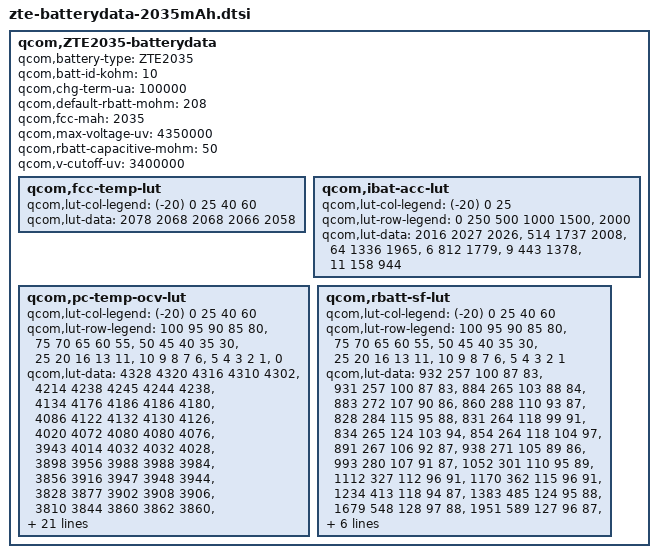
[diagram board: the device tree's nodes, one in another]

qcom,ZTE2035-batterydata {
	qcom,battery-type = "ZTE2035";
	qcom,batt-id-kohm = <10>;
	qcom,chg-term-ua = <100000>;
	qcom,default-rbatt-mohm = <208>;
	qcom,fcc-mah = <2035>;
	qcom,max-voltage-uv = <4350000>;
	qcom,rbatt-capacitive-mohm = <50>;
	qcom,v-cutoff-uv = <3400000>;

	qcom,fcc-temp-lut {
		qcom,lut-col-legend = <(-20) 0 25 40 60>;
		qcom,lut-data = <2078 2068 2068 2066 2058>;
	};

	qcom,ibat-acc-lut {
		qcom,lut-col-legend = <(-20) 0 25>;
		qcom,lut-row-legend = <0 250 500 1000 1500>,
					<2000>;
		qcom,lut-data = <2016 2027 2026>,
				<514 1737 2008>,
				<64 1336 1965>,
				<6 812 1779>,
				<9 443 1378>,
				<11 158 944>;
	};
	qcom,pc-temp-ocv-lut {
		qcom,lut-col-legend = <(-20) 0 25 40 60>;
		qcom,lut-row-legend = <100 95 90 85 80>,
					<75 70 65 60 55>,
					<50 45 40 35 30>,
					<25 20 16 13 11>,
					<10 9 8 7 6>,
					<5 4 3 2 1>,
					<0>;
		qcom,lut-data = <4328 4320 4316 4310 4302>,
				<4214 4238 4245 4244 4238>,
				<4134 4176 4186 4186 4180>,
				<4086 4122 4132 4130 4126>,
				<4020 4072 4080 4080 4076>,
				<3943 4014 4032 4032 4028>,
				<3898 3956 3988 3988 3984>,
				<3856 3916 3947 3948 3944>,
				<3828 3877 3902 3908 3906>,
				<3810 3844 3860 3862 3860>,
				<3794 3815 3831 3832 3830>,
				<3778 3792 3809 3810 3808>,
				<3760 3778 3792 3792 3790>,
				<3741 3764 3777 3777 3775>,
				<3718 3744 3766 3762 3756>,
				<3693 3722 3751 3744 3731>,
				<3664 3706 3729 3722 3708>,
				<3638 3697 3704 3698 3684>,
				<3617 3689 3684 3677 3664>,
				<3602 3680 3676 3670 3659>,
				<3591 3674 3674 3668 3657>,
				<3580 3668 3672 3666 3655>,
				<3566 3658 3668 3663 3652>,
				<3550 3646 3662 3657 3644>,
				<3530 3628 3649 3641 3624>,
				<3506 3602 3618 3607 3586>,
				<3474 3566 3571 3559 3536>,
				<3428 3516 3510 3497 3474>,
				<3358 3443 3428 3414 3390>,
				<3244 3326 3306 3290 3263>,
				<3016 3000 3000 3000 3008>;
	};

	qcom,rbatt-sf-lut {
		qcom,lut-col-legend = <(-20) 0 25 40 60>;
		qcom,lut-row-legend = <100 95 90 85 80>,
					<75 70 65 60 55>,
					<50 45 40 35 30>,
					<25 20 16 13 11>,
					<10 9 8 7 6>,
					<5 4 3 2 1>;
		qcom,lut-data = <932 257 100 87 83>,
				<931 257 100 87 83>,
				<884 265 103 88 84>,
				<883 272 107 90 86>,
				<860 288 110 93 87>,
				<828 284 115 95 88>,
				<831 264 118 99 91>,
				<834 265 124 103 94>,
				<854 264 118 104 97>,
				<891 267 106 92 87>,
				<938 271 105 89 86>,
				<993 280 107 91 87>,
				<1052 301 110 95 89>,
				<1112 327 112 96 91>,
				<1170 362 115 96 91>,
				<1234 413 118 94 87>,
				<1383 485 124 95 88>,
				<1679 548 128 97 88>,
				<1951 589 127 96 87>,
				<2028 575 128 96 88>,
				<2223 594 132 99 89>,
				<2486 617 138 101 90>,
				<2810 642 143 104 92>,
				<3225 669 150 106 92>,
				<3758 702 154 105 90>,
				<4499 739 156 103 90>,
				<5588 790 161 106 92>,
				<7345 859 173 111 94>,
				<10001 975 190 117 100>,
				<15539 1321 223 133 113>;
	};
};
/* TEST_DB_ID=TEST_ID_NOT_SET */
